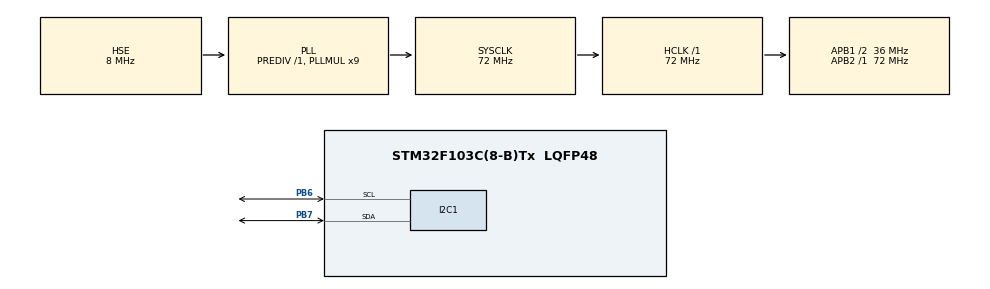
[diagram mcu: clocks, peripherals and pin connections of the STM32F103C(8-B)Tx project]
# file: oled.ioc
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I2C1.I2C_Mode=I2C_Fast
Mcu.Family=STM32F1
Mcu.Name=STM32F103C(8-B)Tx
Mcu.Package=LQFP48
NVIC.PriorityGroup=NVIC_PRIORITYGROUP_4
PA13.Mode=Serial_Wire
PA13.Signal=SYS_JTMS-SWDIO
PA14.Mode=Serial_Wire
PA14.Signal=SYS_JTCK-SWCLK
PB6.Mode=I2C
PB6.Signal=I2C1_SCL
PB7.Mode=I2C
PB7.Signal=I2C1_SDA
PD0-OSC_IN.Mode=HSE-External-Oscillator
PD0-OSC_IN.Signal=RCC_OSC_IN
PD1-OSC_OUT.Mode=HSE-External-Oscillator
PD1-OSC_OUT.Signal=RCC_OSC_OUT
ProjectManager.HeapSize=0x200
ProjectManager.StackSize=0x400
ProjectManager.TargetToolchain=STM32CubeIDE
RCC.AHBFreq_Value=72000000
RCC.APB1CLKDivider=RCC_HCLK_DIV2
RCC.APB1Freq_Value=36000000
RCC.APB1TimFreq_Value=72000000
RCC.APB2Freq_Value=72000000
RCC.APB2TimFreq_Value=72000000
RCC.HCLKFreq_Value=72000000
RCC.PLLMUL=RCC_PLL_MUL9
RCC.PLLSourceVirtual=RCC_PLLSOURCE_HSE
RCC.SYSCLKFreq_VALUE=72000000
RCC.SYSCLKSource=RCC_SYSCLKSOURCE_PLLCLK
RCC.USBFreq_Value=72000000
board=custom

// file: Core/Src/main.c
/* USER CODE BEGIN Header */
/**
  ******************************************************************************
  * @file           : main.c
  * @brief          : Main program body
  ******************************************************************************
  * @attention
  *
  * Copyright (c) 2026 STMicroelectronics.
  * All rights reserved.
  *
  * This software is licensed under terms that can be found in the LICENSE file
  * in the root directory of this software component.
  * If no LICENSE file comes with this software, it is provided AS-IS.
  *
  ******************************************************************************
  */
/* USER CODE END Header */
#include "main.h"
#include "i2c.h"
#include "gpio.h"

/* USER CODE BEGIN Includes */
#include "oled.h"
#include <stdio.h>
/* USER CODE END Includes */

/* USER CODE BEGIN PD */
#define OLED_REFRESH_PERIOD_MS 100U
/* USER CODE END PD */

/* USER CODE BEGIN PV */
static uint32_t oledLastRefreshTick;
/* Watch these variables in the debugger to check the refresh rate. */
volatile uint32_t oledFrameCount = 0U;
volatile uint32_t oledFrameStartMs = 0U;
volatile uint32_t oledFramePeriodMs = 0U;
volatile uint32_t oledRenderTimeMs = 0U;
/* USER CODE END PV */

void SystemClock_Config(void);
/* USER CODE BEGIN PFP */
static void OLED_RenderDemoFrame(void);
/* USER CODE END PFP */

/* USER CODE BEGIN 0 */
static void OLED_RenderDemoFrame(void)
{
  uint32_t startMs = HAL_GetTick();
  char frameText[17]; /* 16 ASCII characters plus the terminator. */

  oledFramePeriodMs = (oledFrameCount == 0U) ? 0U : startMs - oledFrameStartMs;
  oledFrameStartMs = startMs;
  snprintf(frameText, sizeof(frameText), "Frame:%010lu",
           (unsigned long)(oledFrameCount + 1U));

  OLED_NewFrame();
  OLED_PrintASCIIString(0, 0, "OLED 10Hz", &afont16x8, OLED_COLOR_NORMAL);
  OLED_PrintASCIIString(0, 16, frameText, &afont16x8, OLED_COLOR_NORMAL);
  OLED_PrintASCIIString(0, 32, "!@#$%&*+-=?:", &afont16x8, OLED_COLOR_NORMAL);
  OLED_PrintString(32, 48, "刘何瑾瑜", &fontDemo16x16, OLED_COLOR_NORMAL);
  OLED_ShowFrame();

  oledRenderTimeMs = HAL_GetTick() - startMs;
  oledFrameCount++;
}
/* USER CODE END 0 */

int main(void)
{

  /* MCU Configuration--------------------------------------------------------*/

  /* Reset of all peripherals, Initializes the Flash interface and the Systick. */
  HAL_Init();

  /* Configure the system clock */
  SystemClock_Config();

  /* Initialize all configured peripherals */
  MX_GPIO_Init();
  MX_I2C1_Init();
  /* USER CODE BEGIN 2 */
  /* Wait for the OLED power supply, then draw the first frame immediately. */
  HAL_Delay(20);
  OLED_Init();
  oledLastRefreshTick = HAL_GetTick();
  OLED_RenderDemoFrame();
  /* USER CODE END 2 */

  /* Infinite loop */
  while (1)
  {

    /* USER CODE BEGIN 3 */
    uint32_t nowMs = HAL_GetTick();
    /* Count from the frame start, including rendering and I2C transfer time.
     * Unsigned subtraction also works when the HAL tick counter wraps.
     * Rebase to now so an overdue frame never causes a burst of catch-up frames.
     */
    if ((uint32_t)(nowMs - oledLastRefreshTick) >= OLED_REFRESH_PERIOD_MS)
    {
      oledLastRefreshTick = nowMs;
      OLED_RenderDemoFrame();
    }
  }
  /* USER CODE END 3 */
}

void SystemClock_Config(void)
{
  RCC_OscInitTypeDef RCC_OscInitStruct = {0};
  RCC_ClkInitTypeDef RCC_ClkInitStruct = {0};

  /** Initializes the RCC Oscillators according to the specified parameters
  * in the RCC_OscInitTypeDef structure.
  */
  RCC_OscInitStruct.OscillatorType = RCC_OSCILLATORTYPE_HSE;
  RCC_OscInitStruct.HSEState = RCC_HSE_ON;
  RCC_OscInitStruct.HSEPredivValue = RCC_HSE_PREDIV_DIV1;
  RCC_OscInitStruct.HSIState = RCC_HSI_ON;
  RCC_OscInitStruct.PLL.PLLState = RCC_PLL_ON;
  RCC_OscInitStruct.PLL.PLLSource = RCC_PLLSOURCE_HSE;
  RCC_OscInitStruct.PLL.PLLMUL = RCC_PLL_MUL9;
  if (HAL_RCC_OscConfig(&RCC_OscInitStruct) != HAL_OK)
  {
    Error_Handler();
  }

  /** Initializes the CPU, AHB and APB buses clocks
  */
  RCC_ClkInitStruct.ClockType = RCC_CLOCKTYPE_HCLK|RCC_CLOCKTYPE_SYSCLK
                              |RCC_CLOCKTYPE_PCLK1|RCC_CLOCKTYPE_PCLK2;
  RCC_ClkInitStruct.SYSCLKSource = RCC_SYSCLKSOURCE_PLLCLK;
  RCC_ClkInitStruct.AHBCLKDivider = RCC_SYSCLK_DIV1;
  RCC_ClkInitStruct.APB1CLKDivider = RCC_HCLK_DIV2;
  RCC_ClkInitStruct.APB2CLKDivider = RCC_HCLK_DIV1;

  if (HAL_RCC_ClockConfig(&RCC_ClkInitStruct, FLASH_LATENCY_2) != HAL_OK)
  {
    Error_Handler();
  }
}

void Error_Handler(void)
{
  __disable_irq();
  while (1)
  {
  }
}
